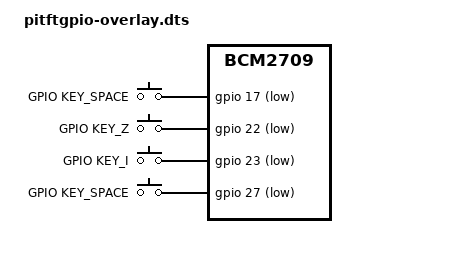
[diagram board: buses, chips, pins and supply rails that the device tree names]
/dts-v1/;
/plugin/;

/ {
	compatible = "brcm,bcm2835", "brcm,bcm2836", "brcm,bcm2708", "brcm,bcm2709";

	fragment@0 {
		target = <&gpio>;
		__overlay__ {
			keypad_pins: keypad_pins {
				brcm,pins = <17 22 23 27>;
				brcm,function = <0>; /* in */
				brcm,pull = <2>; /* up */
			};
		};
	};

	fragment@1 {
		target-path = "/soc";
		__overlay__ {
			keypad: keypad {
				compatible = "gpio-keys";
				#address-cells = <1>;
				#size-cells = <0>;
				pinctrl-names = "default";
				pinctrl-0 = <&keypad_pins>;
				status = "okay";
				#autorepeat;

				button@17 {
					label = "GPIO KEY_SPACE";
					linux,code = <57>;
					gpios = <&gpio 17 1>;
				};
				button@22 {
					label = "GPIO KEY_Z";
					linux,code = <44>;
					gpios = <&gpio 22 1>;
				};
				button@23 {
					label = "GPIO KEY_I";
					linux,code = <23>;
					gpios = <&gpio 23 1>;
				};
				button@27 {
					label = "GPIO KEY_SPACE";
					linux,code = <36>;
					gpios = <&gpio 27 1>;
				};
			};
		};
	};

	__overrides__ {
		keypad =     <&keypad>,"status";
	};
};
